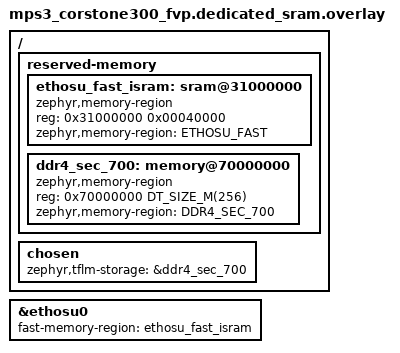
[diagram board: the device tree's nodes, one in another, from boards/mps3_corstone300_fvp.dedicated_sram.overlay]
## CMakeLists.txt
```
# SPDX-FileCopyrightText: Copyright 2021-2022, 2025-2026 Arm Limited and/or its
# SPDX-FileCopyrightText: affiliates <open-source-office@arm.com>
# SPDX-License-Identifier: Apache-2.0

cmake_minimum_required(VERSION 3.28.0)

find_package(Zephyr REQUIRED HINTS $ENV{ZEPHYR_BASE})

project(tflm_ethosu_app)

# Choose model
target_include_directories(app PRIVATE src/models/keyword_spotting_cnn_small_int8)

target_sources(app PRIVATE src/main.cpp src/inference_process.cpp)

# Add platform specific linker source snippet
zephyr_linker_sources_ifdef(CONFIG_SOC_SERIES_MPS3 SECTIONS linker.ld)
zephyr_linker_sources_ifdef(CONFIG_SOC_SERIES_MPS4 SECTIONS linker.ld)

# Optional PMU integration
if(CONFIG_SAMPLE_TFLM_ETHOSU_PMU)
  target_sources(app PRIVATE src/ethosu_pmu_monitor.cpp)
  # Expose configurable PMU event selections via CMake cache.
  # Defaults are chosen per platform; users can override via -DETHOSU_PMU_EVENT_N=TOKEN
  if(CONFIG_ETHOS_U85_128 OR CONFIG_ETHOS_U85_256 OR CONFIG_ETHOS_U85_512 OR CONFIG_ETHOS_U85_1024 OR CONFIG_ETHOS_U85_2048)
    set(ETHOSU_PMU_EVENT_0 ETHOSU_PMU_SRAM_RD_DATA_BEAT_RECEIVED  CACHE STRING "PMU Event #0")
    set(ETHOSU_PMU_EVENT_1 ETHOSU_PMU_SRAM_WR_DATA_BEAT_WRITTEN   CACHE STRING "PMU Event #1")
    set(ETHOSU_PMU_EVENT_2 ETHOSU_PMU_EXT_RD_DATA_BEAT_RECEIVED   CACHE STRING "PMU Event #2")
    set(ETHOSU_PMU_EVENT_3 ETHOSU_PMU_EXT_WR_DATA_BEAT_WRITTEN    CACHE STRING "PMU Event #3")
    set(ETHOSU_PMU_EVENT_4 ETHOSU_PMU_SRAM0_RD_DATA_BEAT_RECEIVED CACHE STRING "PMU Event #4")
    set(ETHOSU_PMU_EVENT_5 ETHOSU_PMU_SRAM1_RD_DATA_BEAT_RECEIVED CACHE STRING "PMU Event #5")
    set(ETHOSU_PMU_EVENT_6 ETHOSU_PMU_SRAM2_RD_DATA_BEAT_RECEIVED CACHE STRING "PMU Event #6")
    set(ETHOSU_PMU_EVENT_7 ETHOSU_PMU_SRAM3_RD_DATA_BEAT_RECEIVED CACHE STRING "PMU Event #7")
    target_compile_definitions(app PRIVATE
      ETHOSU_PMU_EVENT_0=${ETHOSU_PMU_EVENT_0}
      ETHOSU_PMU_EVENT_1=${ETHOSU_PMU_EVENT_1}
      ETHOSU_PMU_EVENT_2=${ETHOSU_PMU_EVENT_2}
      ETHOSU_PMU_EVENT_3=${ETHOSU_PMU_EVENT_3}
      ETHOSU_PMU_EVENT_4=${ETHOSU_PMU_EVENT_4}
      ETHOSU_PMU_EVENT_5=${ETHOSU_PMU_EVENT_5}
      ETHOSU_PMU_EVENT_6=${ETHOSU_PMU_EVENT_6}
      ETHOSU_PMU_EVENT_7=${ETHOSU_PMU_EVENT_7}
    )
  else()
    set(ETHOSU_PMU_EVENT_0 ETHOSU_PMU_AXI0_RD_DATA_BEAT_RECEIVED CACHE STRING "PMU Event #0")
    set(ETHOSU_PMU_EVENT_1 ETHOSU_PMU_AXI0_WR_DATA_BEAT_WRITTEN CACHE STRING "PMU Event #1")
    set(ETHOSU_PMU_EVENT_2 ETHOSU_PMU_AXI1_RD_DATA_BEAT_RECEIVED  CACHE STRING "PMU Event #2")
    set(ETHOSU_PMU_EVENT_3 ETHOSU_PMU_AXI1_WR_DATA_BEAT_WRITTEN  CACHE STRING "PMU Event #3")
    target_compile_definitions(app PRIVATE
      ETHOSU_PMU_EVENT_0=${ETHOSU_PMU_EVENT_0}
      ETHOSU_PMU_EVENT_1=${ETHOSU_PMU_EVENT_1}
      ETHOSU_PMU_EVENT_2=${ETHOSU_PMU_EVENT_2}
      ETHOSU_PMU_EVENT_3=${ETHOSU_PMU_EVENT_3}
    )
  endif()
endif()

# -----------------------------------------------------------------------------
# Vela memory mode -> region mapping used by this sample
# -----------------------------------------------------------------------------
set(_REGION_WEIGHTS      "NPU_REGIONCFG_0")
set(_REGION_SCRATCH      "NPU_REGIONCFG_1")
set(_REGION_FAST_SCRATCH "NPU_REGIONCFG_2")
set(_REGION_CMD_STREAM   "NPU_QCONFIG")

# NOTE:
# We intentionally use zephyr_compile_definitions() here (instead of
# target_compile_definitions(app ...)) because these overrides must be
# visible when the HAL itself is compiled. The HAL sources key
# off NPU_REGIONCFG_n / NPU_QCONFIG at build time (and on Arm Ethos-U85 NPU those
# selections index into MEM_ATTR entries), so the macros need to propagate
# globally through Zephyr's interface. This ensures the overrides are
# consistently picked up regardless of how the sample is built.
if(CONFIG_SAMPLE_TFLM_ETHOSU_MEM_MODE_SHARED_SRAM)
  zephyr_compile_definitions(
    ${_REGION_WEIGHTS}=3
    ${_REGION_SCRATCH}=0
    ${_REGION_FAST_SCRATCH}=0
    ${_REGION_CMD_STREAM}=3)
elseif(CONFIG_SAMPLE_TFLM_ETHOSU_MEM_MODE_DEDICATED_SRAM)
  zephyr_compile_definitions(
    ${_REGION_WEIGHTS}=3
    ${_REGION_SCRATCH}=3
    ${_REGION_FAST_SCRATCH}=0
    ${_REGION_CMD_STREAM}=3)
elseif(CONFIG_SAMPLE_TFLM_ETHOSU_MEM_MODE_SRAM_ONLY)
  zephyr_compile_definitions(
    ${_REGION_WEIGHTS}=0
    ${_REGION_SCRATCH}=0
    ${_REGION_FAST_SCRATCH}=0
    ${_REGION_CMD_STREAM}=0)
endif()
```

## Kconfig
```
# SPDX-FileCopyrightText: Copyright 2022, 2025-2026 Arm Limited and/or its
# SPDX-FileCopyrightText: affiliates <open-source-office@arm.com>
# SPDX-License-Identifier: Apache-2.0

config TAINT_BLOBS_TFLM
	bool
	default y
	select TAINT_BLOBS

config TAINT_BLOBS_TFLM_ETHOSU
	bool "Choose Vela-compiled model targeting Ethos-U"
	default y
	depends on ETHOS_U_ARM || ETHOS_U_NUMAKER || ETHOS_U_RENESAS || ETHOS_U_INFINEON
	select TAINT_BLOBS_TFLM

config SAMPLE_TFLM_ETHOSU_PMU
	bool "Enable PMU counters in sample"
	depends on ETHOS_U
	help
	  Enable PMU counters for this sample. When enabled,
	  the sample collects cycle and selected event counters per inference.

choice SAMPLE_TFLM_ETHOSU_MEM_MODE
	prompt "Vela memory mode (sample override)"
	default SAMPLE_TFLM_ETHOSU_MEM_MODE_HAL_DEFAULT
	depends on ETHOS_U
	help
	  Configure memory mode used by Vela.

	  - On Arm Ethos-U55 NPU and Arm Ethos-U65 NPU:
	    REGIONCFG values 0/1 route to AXI0 (governed by AXI_LIMIT0/1, typically on-chip SRAM),
	    REGIONCFG values 2/3 route to AXI1 (governed by AXI_LIMIT2/3, typically external memory).
	    (U55: AXI1 is read-only; U65: both ports are read/write.)
	    This mapping is architectural (fixed).

	  - On Arm Ethos-U85 NPU:
	    REGIONCFG values 0/1 select MEM_ATTR[0/1] (typically the SRAM AXI port),
	    REGIONCFG values 2/3 select MEM_ATTR[2/3] (typically the external AXI port).
	    These defaults come from the HAL but can be changed by redefining
	    NPU_MEM_ATTR_[0-3] if your system requires different attributes.

	  The chosen mode must match the mode used when compiling the model with Vela.

config SAMPLE_TFLM_ETHOSU_MEM_MODE_HAL_DEFAULT
	bool "HAL default"
	help
	  Do not override the HAL defaults for region mapping.
	  The HAL determines NPU_REGIONCFG_n and NPU_QCONFIG.

config SAMPLE_TFLM_ETHOSU_MEM_MODE_SHARED_SRAM
	bool "Shared_Sram (weights=3, scratch=0, fast_scratch=0, cmd_stream=3)"
	help
	  Match Vela's Shared_Sram mode:
	  - U55/U65: weights & command stream -> AXI1 / AXI_LIMIT3 (typically external),
	             scratch & fast_scratch -> AXI0 / AXI_LIMIT0 (typically on-chip)
	  - U85:     weights & command stream -> MEM_ATTR[3] (typically external),
	             scratch & fast_scratch -> MEM_ATTR[0] (typically on-chip)

config SAMPLE_TFLM_ETHOSU_MEM_MODE_DEDICATED_SRAM
	bool "Dedicated_Sram (weights=3, scratch=3, fast_scratch=0, cmd_stream=3)"
	depends on !(ETHOS_U55_64 || ETHOS_U55_128 || ETHOS_U55_256)
	help
	  Match Vela's Dedicated_Sram mode:
	  - U55/U65: weights, scratch & command stream -> AXI1 / AXI_LIMIT3 (typically external),
	             fast_scratch -> AXI0 / AXI_LIMIT0 (typically on-chip)
	  - U85:     weights, scratch & command stream -> MEM_ATTR[3] (typically external),
	             fast_scratch -> MEM_ATTR[0] (typically on-chip)
	  Not supported on Arm Ethos-U55 NPU.

config SAMPLE_TFLM_ETHOSU_MEM_MODE_SRAM_ONLY
	bool "Sram_Only (weights=1, scratch=0, fast_scratch=0, cmd_stream=1)"
	help
	  Match Vela's SRAM_Only mode (everything on the SRAM side):
	  - U55/U65: weights & command stream -> AXI0 / AXI_LIMIT1,
	             scratch & fast_scratch -> AXI0 / AXI_LIMIT0
	  - U85:     weights & command stream -> MEM_ATTR[1] (SRAM port),
	             scratch & fast_scratch -> MEM_ATTR[0] (SRAM port)
endchoice

source "Kconfig.zephyr"
```

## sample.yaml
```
sample:
  description: Demonstration of the Arm Ethos-U NPU
  name: Arm Ethos-U NPU sample
tests:
  sample.drivers.tflm_ethosu:
    tags:
      - NPU
    modules:
      - tflite-micro
    filter: dt_compat_enabled("arm,ethos-u")
    build_only: true
    platform_allow:
      - mps3/corstone300/fvp
      - kit_pse84_ai/pse846gps2dbzc4a/m55
    integration_platforms:
      - mps3/corstone300/fvp
      - kit_pse84_ai/pse846gps2dbzc4a/m55
  sample.drivers.tflm_ethosu_sram_only:
    tags:
      - NPU
    modules:
      - tflite-micro
    filter: dt_compat_enabled("arm,ethos-u")
    build_only: true
    platform_allow:
      - mps3/corstone300/fvp
    integration_platforms:
      - mps3/corstone300/fvp
    extra_configs:
      - CONFIG_SAMPLE_TFLM_ETHOSU_MEM_MODE_SRAM_ONLY=y
    extra_args:
      - DTC_OVERLAY_FILE=boards/mps3_corstone300_fvp.sram_only.overlay
  sample.drivers.tflm_ethosu_dedicated_sram:
    tags:
      - NPU
    modules:
      - tflite-micro
    filter: dt_compat_enabled("arm,ethos-u")
    build_only: true
    platform_allow:
      - mps3/corstone300/fvp
    integration_platforms:
      - mps3/corstone300/fvp
    extra_configs:
      - CONFIG_SAMPLE_TFLM_ETHOSU_MEM_MODE_DEDICATED_SRAM=y
    extra_args:
      - CONFIG_ETHOS_U65_256=y
      - DTC_OVERLAY_FILE=boards/mps3_corstone300_fvp.dedicated_sram.overlay
  sample.drivers.tflm_ethosu_mps4_u85_pmu:
    tags:
      - NPU
    modules:
      - tflite-micro
    filter: dt_compat_enabled("arm,ethos-u")
    build_only: true
    platform_allow:
      - mps4/corstone320/fvp
    integration_platforms:
      - mps4/corstone320/fvp
    extra_configs:
      - CONFIG_SAMPLE_TFLM_ETHOSU_MEM_MODE_SRAM_ONLY=y
    extra_args:
      - CONFIG_ETHOS_U85_2048=y
      - CONFIG_SAMPLE_TFLM_ETHOSU_PMU=y
      - DTC_OVERLAY_FILE="boards/mps4_corstone320_fvp.ta.overlay;boards/mps4_corstone320_fvp.sram_only.overlay"
```

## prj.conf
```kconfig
#application default configuration
# include TFLM based on CMSIS NN optimization and ETHOSU acceleration
CONFIG_CPP=y
CONFIG_STD_CPP17=y
CONFIG_TENSORFLOW_LITE_MICRO=y
CONFIG_ETHOS_U=y
CONFIG_HEAP_MEM_POOL_SIZE=16384
CONFIG_LOG=y
CONFIG_REQUIRES_FLOAT_PRINTF=y
```

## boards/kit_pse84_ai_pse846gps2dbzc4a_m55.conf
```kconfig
# Board-specific configuration for kit_pse84_ai
# Increase main thread stack to handle C++ STL and TFLite/Ethos-U init overhead
CONFIG_MAIN_STACK_SIZE=4096
```

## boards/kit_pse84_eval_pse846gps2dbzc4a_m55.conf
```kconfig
# Board-specific configuration for kit_pse84_eval
# Increase main thread stack to handle C++ STL and TFLite/Ethos-U init overhead
CONFIG_MAIN_STACK_SIZE=4096
```

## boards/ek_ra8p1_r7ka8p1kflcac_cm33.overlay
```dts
/*
 * Copyright (c) 2025 Renesas Electronics Corporation
 * SPDX-License-Identifier: Apache-2.0
 */

&npu0 {
	interrupts = <95 1>;
	interrupt-names = "npu-irq";
	status = "okay";
};
```

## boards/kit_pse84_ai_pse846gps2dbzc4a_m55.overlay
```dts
/*
 * SPDX-FileCopyrightText: <text>Copyright (c) 2026 Infineon Technologies AG,
 * or an affiliate of Infineon Technologies AG. All rights reserved.</text>
 *
 * SPDX-License-Identifier: Apache-2.0
 */

&npu0 {
	status = "okay";
};
```

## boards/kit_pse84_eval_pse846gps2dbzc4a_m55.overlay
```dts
/*
 * SPDX-FileCopyrightText: Copyright (c) 2026 Infineon Technologies AG,
 * SPDX-FileCopyrightText: or an affiliate of Infineon Technologies AG. All rights reserved.
 *
 * SPDX-License-Identifier: Apache-2.0
 */

&npu0 {
	status = "okay";
};
```

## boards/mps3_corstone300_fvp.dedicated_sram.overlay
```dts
/*
 * SPDX-FileCopyrightText: Copyright 2026 Arm Limited and/or its
 * SPDX-FileCopyrightText: affiliates <open-source-office@arm.com>
 * SPDX-License-Identifier: Apache-2.0
 */

/ {
	reserved-memory {
		ranges;
		#address-cells = <1>;
		#size-cells = <1>;

		/* 256 KiB fast scratch for the NPU */
		ethosu_fast_isram: sram@31000000 {
			compatible = "zephyr,memory-region", "mmio-sram";
			reg = <0x31000000 0x00040000>;
			zephyr,memory-region = "ETHOSU_FAST";
		};

		/* Define a dedicated secure DDR4 slice (256 MiB) at 0x7000_0000 */
		ddr4_sec_700: memory@70000000 {
			compatible = "zephyr,memory-region";
			reg = <0x70000000 DT_SIZE_M(256)>;
			zephyr,memory-region = "DDR4_SEC_700";
		};
	};

	chosen {
		/* TFLM buffers live in external DDR4 */
		zephyr,tflm-storage = &ddr4_sec_700; /* TFLM buffers in secure DDR4 @ 0x7000_0000 */
	};
};

&ethosu0 {
	fast-memory-region = <&ethosu_fast_isram>;
};
```

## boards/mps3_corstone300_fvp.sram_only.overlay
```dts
/*
 * SPDX-FileCopyrightText: Copyright 2026 Arm Limited and/or its
 * SPDX-FileCopyrightText: affiliates <open-source-office@arm.com>
 * SPDX-License-Identifier: Apache-2.0
 */

/ {
	chosen {
		/* Writable on-chip ISRAM for TFLM buffers */
		zephyr,tflm-storage = &isram;
	};
};
```

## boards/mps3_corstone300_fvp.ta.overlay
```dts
/*
 * SPDX-FileCopyrightText: Copyright 2025 Arm Limited and/or its
 * SPDX-FileCopyrightText: affiliates <open-source-office@arm.com>
 * SPDX-License-Identifier: Apache-2.0
 */

&ethosu0 {
	#address-cells = <1>;
	#size-cells = <0>;

	/*
	 * Corstone-300 FVP: TAs on AXI ports (SRAM, Flash/DRAM)
	 * Vela: System_Config.Ethos_U55_High_End_Embedded
	 * (core_clock=500 MHz, SRAM=4 GB/s, Flash=0.5 GB/s)
	 */

	ta0: timing-adapter@48103000 {
		compatible = "arm,axi-timing-adapter";
		reg = <0x48103000>;
		status = "okay";

		version = <0x1117>;
		maxr = <8>;
		maxw = <8>;
		maxrw = <0>;
		rlatency = <32>;
		wlatency = <32>;
		pulse-on = <3999>;
		pulse-off = <1>;
		bwcap = <4000>;
		mode = <1>;
		perfctrl = <0>;
		perfcnt = <0>;
		histbin = <0>;
		histcnt = <0>;
	};

	ta1: timing-adapter@48103200 {
		compatible = "arm,axi-timing-adapter";
		reg = <0x48103200>;
		status = "okay";

		version = <0x1117>;
		maxr = <2>;
		maxw = <0>;
		maxrw = <0>;
		rlatency = <64>;
		wlatency = <0>;
		pulse-on = <320>;
		pulse-off = <80>;
		bwcap = <50>;
		mode = <1>;
		perfctrl = <0>;
		perfcnt = <0>;
		histbin = <0>;
		histcnt = <0>;
	};
};
```

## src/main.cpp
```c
/*
 * Copyright 2019-2022 Arm Limited and/or its affiliates <open-source-office@arm.com>
 *
 * SPDX-License-Identifier: Apache-2.0
 */

/****************************************************************************
 * Includes
 ****************************************************************************/

#include "inference_process.hpp"

#include <inttypes.h>
#include <string>
#include <stdio.h>
#include <vector>
#include <zephyr/kernel.h>

/* Model data */
#include <input.h>
#include <model.h>
#include <output.h>

using namespace std;
using namespace InferenceProcess;

/****************************************************************************
 * Defines
 ****************************************************************************/

/* Number of worker threads running the inferences. There should typically be
 * one worker thread per NPU. */
#ifndef NUM_INFERENCE_TASKS
#define NUM_INFERENCE_TASKS 1
#endif

/* Number of sender tasks, that post inference requests to the worker threads. */
#ifndef NUM_JOB_TASKS
#define NUM_JOB_TASKS 2
#endif

/* Number of inferences per sender task. */
#ifndef NUM_JOBS_PER_TASK
#define NUM_JOBS_PER_TASK 2
#endif

/* Tensor arena size */
#ifdef TENSOR_ARENA_SIZE /* If defined in model.h */
#define TENSOR_ARENA_SIZE_PER_INFERENCE TENSOR_ARENA_SIZE
#else /* If not defined, use maximum available */
#define TENSOR_ARENA_SIZE_PER_INFERENCE 2000000 / NUM_INFERENCE_TASKS
#endif

/****************************************************************************
 * InferenceJob
 ****************************************************************************/

namespace
{
struct InferenceProcessParams {
	InferenceProcessParams() : tensorArena(nullptr), arenaSize(0)
	{
	}

	InferenceProcessParams(k_queue *_queue, uint8_t *_tensorArena, size_t _arenaSize)
		: queueHandle(_queue), tensorArena(_tensorArena), arenaSize(_arenaSize)
	{
	}

	k_queue *queueHandle;
	uint8_t *tensorArena;
	size_t arenaSize;
};

/* Wrapper around InferenceProcess::InferenceJob. Adds responseQueue and status
 * for Zephyr multi-tasking purposes.& */
struct xInferenceJob : public InferenceJob {
	xInferenceJob() : InferenceJob(), responseQueue(nullptr), status(false)
	{
	}

	xInferenceJob(const string &_name, const DataPtr &_networkModel,
		      const vector<DataPtr> &_input, const vector<DataPtr> &_output,
		      const vector<DataPtr> &_expectedOutput, k_queue *_queue)
		: InferenceJob(_name, _networkModel, _input, _output, _expectedOutput),
		  responseQueue(_queue), status(false)
	{
	}

	k_queue *responseQueue;
	bool status;
};

/* Number of total completed jobs, needed to exit application correctly if
 * NUM_JOB_TASKS > 1 */
volatile int totalCompletedJobs = 0;

/* TensorArena static initialisation */
const size_t arenaSize = TENSOR_ARENA_SIZE_PER_INFERENCE;

TENSOR_ARENA_ATTR
uint8_t inferenceProcessTensorArena[NUM_INFERENCE_TASKS][arenaSize];

/* Allocate and initialize heap */
void *allocateHeap(const size_t size)
{
	k_heap *heap = static_cast<k_heap *>(k_malloc(sizeof(k_heap)));
	uint8_t *buf = static_cast<uint8_t *>(k_malloc(size));

	if ((buf == nullptr) || (heap == nullptr)) {
		printf("Heap allocation failed. heap=%p, buf=%p, size=%zu\n", heap, buf, size);
		exit(1);
	}

	k_heap_init(heap, buf, size);

	return static_cast<void *>(heap);
}

/* inferenceProcessTask - Run jobs from queue with available driver */
void inferenceProcessTask(void *_name, void *heap, void *_params)
{
	string *name = static_cast<string *>(_name);
	InferenceProcessParams *params = static_cast<InferenceProcessParams *>(_params);

	/* Assign the pre allocated heap - used in the k_queue_alloc_append */
	k_thread_heap_assign(k_current_get(), static_cast<k_heap *>(heap));

	class InferenceProcess inferenceProcess(params->tensorArena, params->arenaSize);

	for (;;) {
		/* Receive inference job */
		xInferenceJob *job =
			static_cast<xInferenceJob *>(k_queue_get(params->queueHandle, Z_FOREVER));

		printf("%s: Received inference job. job=%p\n", name->c_str(), job);

		/* Run inference */
		job->status = inferenceProcess.runJob(*job);

		printf("%s: Sending inference response. job=%p\n", name->c_str(), job);

		/* Return inference message */
		int ret = k_queue_alloc_append(job->responseQueue, job);
		if (0 != ret) {
			printf("%s: Failed to send message\n", name->c_str());
			exit(1);
		}
	}

	k_thread_abort(k_current_get());

	CODE_UNREACHABLE;
}

/* inferenceSenderTask - Creates NUM_INFERENCE_JOBS jobs, queues them, and then
 * listens for completion status */
void inferenceSenderTask(void *_name, void *heap, void *_queue)
{
	string *name = static_cast<string *>(_name);
	k_queue *inferenceQueue = static_cast<k_queue *>(_queue);
	int ret = 0;

	/* Assign the pre allocated heap - used in the k_queue_alloc_append */
	k_thread_heap_assign(k_current_get(), static_cast<k_heap *>(heap));

	/* Create queue for response messages */
	k_queue senderQueue;
	k_queue_init(&senderQueue);

	/* Loop over all jobs and push them to inference queue */
	xInferenceJob jobs[NUM_JOBS_PER_TASK];
	for (int n = 0; n < NUM_JOBS_PER_TASK; n++) {
		auto &job = jobs[n];
		job = xInferenceJob(modelName, DataPtr(networkModelData, sizeof(networkModelData)),
				    { DataPtr(inputData, sizeof(inputData)) }, {},
				    { DataPtr(expectedOutputData, sizeof(expectedOutputData)) },
				    &senderQueue);

		printf("%s: Sending inference. job=%p, name=%s\n", name->c_str(), &job,
		       job.name.c_str());

		/* Queue job */
		ret = k_queue_alloc_append(inferenceQueue, &job);
		if (0 != ret) {
			printf("%s: Failed to send message\n", name->c_str());
			exit(1);
		}
	}

	/* Listen for completion status */
	do {
		xInferenceJob *job =
			static_cast<xInferenceJob *>(k_queue_get(&senderQueue, Z_FOREVER));

		printf("%s: Received job response. job=%p, status=%u\n", name->c_str(), job,
		       job->status);

		totalCompletedJobs++;

		ret += job->status;
		if (job->status != 0) {
			break;
		}
	} while (totalCompletedJobs < NUM_JOBS_PER_TASK * NUM_JOB_TASKS);

	exit(ret);
}

} /* namespace */

/* Zephyr application. NOTE: Additional tasks may require increased heap size. */
int main()
{
	struct {
		k_thread thread;
		k_tid_t id;
	} threads[NUM_JOB_TASKS + NUM_INFERENCE_TASKS];
	size_t nthreads = 0;

	/* Allocate one global heap for all threads */
	void *heapPtr = allocateHeap(256);

	k_queue inferenceQueue;
	k_queue_init(&inferenceQueue);

	/* inferenceSender tasks to create and queue the jobs */
	const size_t inferenceSenderStackSize = 2048;
	static K_THREAD_STACK_ARRAY_DEFINE(inferenceSenderStacks, NUM_JOB_TASKS,
					   inferenceSenderStackSize);
	for (int n = 0; n < NUM_JOB_TASKS; n++) {
		auto &thread = threads[nthreads];
		string *name = new string("sender " + to_string(n));

		thread.id = k_thread_create(&thread.thread, inferenceSenderStacks[n],
					    inferenceSenderStackSize, inferenceSenderTask,
					    name, heapPtr, &inferenceQueue, 3, 0, K_FOREVER);
		if (thread.id == 0) {
			printf("Failed to create 'inferenceSenderTask%i'\n", n);
			exit(1);
		}

		nthreads++;
	}

	/* Create inferenceProcess tasks to process the queued jobs */
	InferenceProcessParams taskParams[NUM_INFERENCE_TASKS];
	const size_t inferenceProcessStackSize = 8192;
	static K_THREAD_STACK_ARRAY_DEFINE(inferenceProcessStacks, NUM_INFERENCE_TASKS,
					   inferenceProcessStackSize);
	for (int n = 0; n < NUM_INFERENCE_TASKS; n++) {
		auto &thread = threads[nthreads];
		auto &taskParam = taskParams[n];
		taskParam = InferenceProcessParams(&inferenceQueue, inferenceProcessTensorArena[n],
						   arenaSize);
		string *name = new string("runner " + to_string(n));

		thread.id = k_thread_create(&thread.thread, inferenceProcessStacks[n],
					    inferenceProcessStackSize, inferenceProcessTask,
					    name, heapPtr, &taskParam, 2, 0, K_FOREVER);
		if (thread.id == 0) {
			printf("Failed to create 'inferenceProcessTask%i'\n", n);
			exit(1);
		}

		nthreads++;
	}

	/* start Scheduler */
	for (size_t n = 0; n < nthreads; n++) {
		k_thread_start(threads[n].id);
	}

	/* put the task in the lowest priority */
	k_thread_priority_set(k_current_get(), 4);

	/* Safety belt */
	k_thread_suspend(k_current_get());

	printf("Zephyr application failed to initialise \n");

	return 1;
}
```

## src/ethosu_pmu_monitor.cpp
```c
/*
 * SPDX-FileCopyrightText: Copyright 2025 Arm Limited and/or its
 * SPDX-FileCopyrightText: affiliates <open-source-office@arm.com>
 * SPDX-License-Identifier: Apache-2.0
 */

/* PMU integration for Ethos-U in Zephyr TFLM sample */

#include <ethosu_driver.h>
#include <pmu_ethosu.h>

#include <cinttypes>
#include <cstdio>

/* Selected PMU events (configured via CMake definitions ETHOSU_PMU_EVENT_N) */
static const enum ethosu_pmu_event_type pmu_events[ETHOSU_PMU_NCOUNTERS] = {
	ETHOSU_PMU_EVENT_0, ETHOSU_PMU_EVENT_1, ETHOSU_PMU_EVENT_2, ETHOSU_PMU_EVENT_3,
#if (ETHOSU_PMU_NCOUNTERS > 4)
	ETHOSU_PMU_EVENT_4, ETHOSU_PMU_EVENT_5, ETHOSU_PMU_EVENT_6, ETHOSU_PMU_EVENT_7,
#endif
};

static inline uint32_t pmu_counter_mask(uint32_t idx)
{
	switch (idx) {
	case 0:
		return ETHOSU_PMU_CNT1_Msk;
	case 1:
		return ETHOSU_PMU_CNT2_Msk;
	case 2:
		return ETHOSU_PMU_CNT3_Msk;
	case 3:
		return ETHOSU_PMU_CNT4_Msk;
#if (ETHOSU_PMU_NCOUNTERS > 4)
	case 4:
		return ETHOSU_PMU_CNT5_Msk;
	case 5:
		return ETHOSU_PMU_CNT6_Msk;
	case 6:
		return ETHOSU_PMU_CNT7_Msk;
	case 7:
		return ETHOSU_PMU_CNT8_Msk;
#endif
	default:
		return 0;
	}
}

extern "C" void ethosu_inference_begin(struct ethosu_driver *drv, void *)
{
	ETHOSU_PMU_Enable(drv);

	for (uint32_t i = 0; i < ETHOSU_PMU_NCOUNTERS; ++i) {
		ETHOSU_PMU_Set_EVTYPER(drv, i, pmu_events[i]);
		ETHOSU_PMU_CNTR_Enable(drv, pmu_counter_mask(i));
	}

	ETHOSU_PMU_PMCCNTR_CFG_Set_Stop_Event(drv, ETHOSU_PMU_NPU_IDLE);
	ETHOSU_PMU_PMCCNTR_CFG_Set_Start_Event(drv, ETHOSU_PMU_NPU_ACTIVE);
	ETHOSU_PMU_CNTR_Enable(drv, ETHOSU_PMU_CCNT_Msk);
	ETHOSU_PMU_CYCCNT_Reset(drv);
	ETHOSU_PMU_EVCNTR_ALL_Reset(drv);
}

extern "C" void ethosu_inference_end(struct ethosu_driver *drv, void *)
{
	const uint64_t cycles = ETHOSU_PMU_Get_CCNTR(drv);

	uint32_t pmu_values[ETHOSU_PMU_NCOUNTERS] = {};
	for (uint32_t i = 0; i < ETHOSU_PMU_NCOUNTERS; ++i) {
		pmu_values[i] = ETHOSU_PMU_Get_EVCNTR(drv, i);
	}
	ETHOSU_PMU_Disable(drv);

	printf("\nEthos-U PMU report:\n");
	printf("ethosu_pmu_cycle_cntr : %" PRIu64 "\n", cycles);
	for (uint32_t i = 0; i < ETHOSU_PMU_NCOUNTERS; ++i) {
		printf("ethosu_pmu_cntr%" PRIu32 " : %" PRIu32 "\n", i, pmu_values[i]);
	}
}
```

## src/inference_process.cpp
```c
/*
 * Copyright 2019-2022 Arm Limited and/or its affiliates <open-source-office@arm.com>
 *
 * SPDX-License-Identifier: Apache-2.0
 */

#include "inference_process.hpp"

#include <tensorflow/lite/micro/micro_mutable_op_resolver.h>
#include <tensorflow/lite/micro/micro_log.h>
#include <tensorflow/lite/micro/micro_interpreter.h>
#include <tensorflow/lite/micro/micro_profiler.h>
#include <tensorflow/lite/schema/schema_generated.h>

#include <inttypes.h>
#include <zephyr/kernel.h>
#include <zephyr/cache.h>

using namespace std;

namespace
{
bool copyOutput(const TfLiteTensor &src, InferenceProcess::DataPtr &dst)
{
	if (dst.data == nullptr) {
		return false;
	}

	if (src.bytes > dst.size) {
		printf("Tensor size mismatch (bytes): actual=%zu, expected=%zu.\n", src.bytes,
		       dst.size);
		return true;
	}

	copy(src.data.uint8, src.data.uint8 + src.bytes, static_cast<uint8_t *>(dst.data));
	dst.size = src.bytes;

	return false;
}

} /* namespace */

namespace InferenceProcess
{
DataPtr::DataPtr(void *_data, size_t _size) : data(_data), size(_size)
{
}

void DataPtr::invalidate()
{
	sys_cache_data_invd_range(data, size);
}

void DataPtr::clean()
{
	sys_cache_data_flush_range(data, size);
}

InferenceJob::InferenceJob()
{
}

InferenceJob::InferenceJob(const string &_name, const DataPtr &_networkModel,
			   const vector<DataPtr> &_input, const vector<DataPtr> &_output,
			   const vector<DataPtr> &_expectedOutput)
	: name(_name), networkModel(_networkModel), input(_input), output(_output),
	  expectedOutput(_expectedOutput)
{
}

void InferenceJob::invalidate()
{
	networkModel.invalidate();

	for (auto &it : input) {
		it.invalidate();
	}

	for (auto &it : output) {
		it.invalidate();
	}

	for (auto &it : expectedOutput) {
		it.invalidate();
	}
}

void InferenceJob::clean()
{
	networkModel.clean();

	for (auto &it : input) {
		it.clean();
	}

	for (auto &it : output) {
		it.clean();
	}

	for (auto &it : expectedOutput) {
		it.clean();
	}
}

bool InferenceProcess::runJob(InferenceJob &job)
{
	/* Get model handle and verify that the version is correct */
	const tflite::Model *model = ::tflite::GetModel(job.networkModel.data);
	if (model->version() != TFLITE_SCHEMA_VERSION) {
		printf("Model schema version unsupported: version=%" PRIu32 ", supported=%d.\n",
		       model->version(), TFLITE_SCHEMA_VERSION);
		return true;
	}

	/* Create the TFL micro interpreter */
#ifdef CONFIG_TAINT_BLOBS_TFLM_ETHOSU
	tflite::MicroMutableOpResolver <1> resolver;
	resolver.AddEthosU();
#else
	tflite::MicroMutableOpResolver <4> resolver;
	resolver.AddReshape();
	resolver.AddConv2D();
	resolver.AddFullyConnected();
	resolver.AddSoftmax();
#endif
	tflite::MicroInterpreter interpreter(model, resolver, tensorArena, tensorArenaSize);

	/* Allocate tensors */
	TfLiteStatus allocate_status = interpreter.AllocateTensors();
	if (allocate_status != kTfLiteOk) {
		printf("Failed to allocate tensors for inference. job=%p\n", &job);
		return true;
	}

	if (job.input.size() != interpreter.inputs_size()) {
		printf("Number of job and network inputs do not match. input=%zu, network=%zu\n",
		       job.input.size(), interpreter.inputs_size());
		return true;
	}

	/* Copy input data */
	for (size_t i = 0; i < interpreter.inputs_size(); ++i) {
		const DataPtr &input = job.input[i];
		const TfLiteTensor *tensor = interpreter.input(i);

		if (input.size != tensor->bytes) {
			printf("Input tensor size mismatch. index=%zu, input=%zu, network=%zu\n", i,
			       input.size, tensor->bytes);
			return true;
		}

		copy(static_cast<char *>(input.data), static_cast<char *>(input.data) + input.size,
		     tensor->data.uint8);
	}

	/* Run the inference */
	TfLiteStatus invoke_status = interpreter.Invoke();
	if (invoke_status != kTfLiteOk) {
		printf("Invoke failed for inference. job=%s\n", job.name.c_str());
		return true;
	}

	/* Copy output data */
	if (job.output.size() > 0) {
		if (interpreter.outputs_size() != job.output.size()) {
			printf("Number of job and network outputs do not match. job=%zu, network=%zu\n",
			       job.output.size(), interpreter.outputs_size());
			return true;
		}

		for (unsigned i = 0; i < interpreter.outputs_size(); ++i) {
			if (copyOutput(*interpreter.output(i), job.output[i])) {
				return true;
			}
		}
	}

	if (job.expectedOutput.size() > 0) {
		if (job.expectedOutput.size() != interpreter.outputs_size()) {
			printf("Number of job and network expected outputs do not match. job=%zu, network=%zu\n",
			       job.expectedOutput.size(), interpreter.outputs_size());
			return true;
		}

		for (unsigned int i = 0; i < interpreter.outputs_size(); i++) {
			const DataPtr &expected = job.expectedOutput[i];
			const TfLiteTensor *output = interpreter.output(i);

			if (expected.size != output->bytes) {
				printf("Expected output tensor size mismatch. index=%u, expected=%zu, network=%zu\n",
				       i, expected.size, output->bytes);
				return true;
			}

			for (unsigned int j = 0; j < output->bytes; ++j) {
				if (output->data.uint8[j] !=
				    static_cast<uint8_t *>(expected.data)[j]) {
					printf("Expected output tensor data mismatch. index=%u, offset=%u, expected=%02x, network=%02x\n",
					       i, j, static_cast<uint8_t *>(expected.data)[j],
					       output->data.uint8[j]);
					return true;
				}
			}
		}
	}

	return false;
}

} /* namespace InferenceProcess */
```

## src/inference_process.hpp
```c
/*
 * Copyright 2019-2022 Arm Limited and/or its affiliates <open-source-office@arm.com>
 *
 * SPDX-License-Identifier: Apache-2.0
 */

#pragma once

#include <array>
#include <queue>
#include <stdlib.h>
#include <string>
#include <vector>
#include <cstdint>

namespace InferenceProcess
{
struct DataPtr {
	void *data;
	size_t size;

	DataPtr(void *data = nullptr, size_t size = 0);

	void invalidate();
	void clean();
};

struct InferenceJob {
	std::string name;
	DataPtr networkModel;
	std::vector<DataPtr> input;
	std::vector<DataPtr> output;
	std::vector<DataPtr> expectedOutput;

	InferenceJob();
	InferenceJob(const std::string &name, const DataPtr &networkModel,
		     const std::vector<DataPtr> &input, const std::vector<DataPtr> &output,
		     const std::vector<DataPtr> &expectedOutput);

	void invalidate();
	void clean();
};

class InferenceProcess {
    public:
	InferenceProcess(uint8_t *_tensorArena, size_t _tensorArenaSize)
		: tensorArena(_tensorArena), tensorArenaSize(_tensorArenaSize)
	{
	}

	bool runJob(InferenceJob &job);

    private:
	uint8_t *tensorArena;
	const size_t tensorArenaSize;
};
} /* namespace InferenceProcess */
```

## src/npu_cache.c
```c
/*
 * Copyright (c) 2025 Nuvoton Technology Corporation.
 *
 * SPDX-License-Identifier: Apache-2.0
 */

#include <stdint.h>
#include <stddef.h>
#include <soc.h>
#include <zephyr/cache.h>

/*******************************************************************************
 * Re-implementation/Overrides __((weak)) symbol functions from ethosu_driver.c
 *******************************************************************************/

#ifndef CONFIG_NOCACHE_MEMORY

void ethosu_flush_dcache(uint32_t *p, size_t bytes)
{
	if (p && bytes) {
		sys_cache_data_flush_range((void *)p, bytes);
	}
}

void ethosu_invalidate_dcache(uint32_t *p, size_t bytes)
{
	if (p && bytes) {
		sys_cache_data_invd_range((void *)p, bytes);
	}
}

#endif
```
